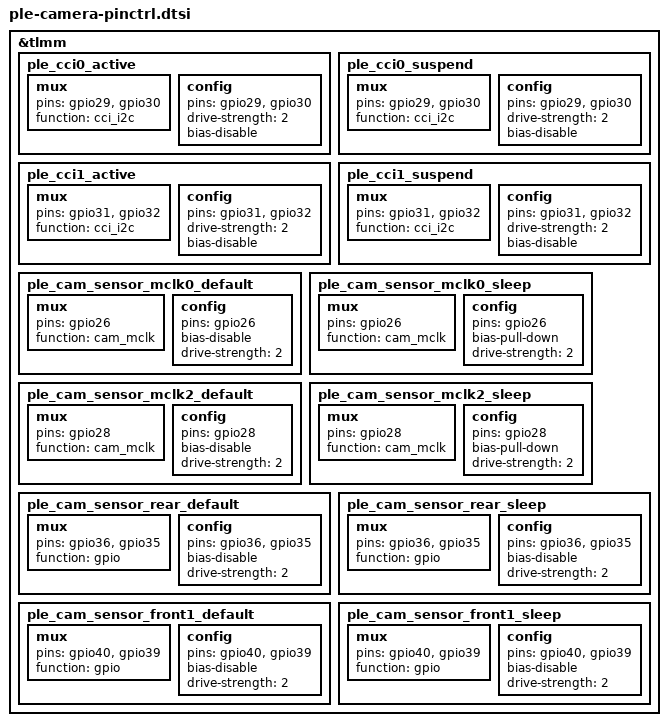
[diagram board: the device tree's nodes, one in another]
// SPDX-License-Identifier: GPL-2.0-only
/* Copyright (c) 2015-2016, The Linux Foundation. All rights reserved.
 * Exact PLE619F pin groups from HMD d548dae4af7fa5a75be88ce2e93f95ad4c867777,
 * msm8937-pinctrl-PLE.dtsi. Local labels avoid generic board assumptions.
 */
&tlmm {
	ple_cci0_active: ple_cci0_active {
				/* cci0 active state */
				mux {
					/* CLK, DATA */
					pins = "gpio29", "gpio30";
					function = "cci_i2c";
				};

				config {
					pins = "gpio29", "gpio30";
					drive-strength = <2>; /* 2 MA */
					bias-disable; /* No PULL */
				};
			};
	ple_cci0_suspend: ple_cci0_suspend {
				/* cci0 suspended state */
				mux {
					/* CLK, DATA */
					pins = "gpio29", "gpio30";
					function = "cci_i2c";
				};

				config {
					pins = "gpio29", "gpio30";
					drive-strength = <2>; /* 2 MA */
					bias-disable; /* No PULL */
				};
			};
	ple_cci1_active: ple_cci1_active {
				/* cci1 active state */
				mux {
					/* CLK, DATA */
					pins = "gpio31", "gpio32";
					function = "cci_i2c";
				};

				config {
					pins = "gpio31", "gpio32";
					drive-strength = <2>; /* 2 MA */
					bias-disable; /* No PULL */
				};
			};
	ple_cci1_suspend: ple_cci1_suspend {
				/* cci1 suspended state */
				mux {
					/* CLK, DATA */
					pins = "gpio31", "gpio32";
					function = "cci_i2c";
				};

				config {
					pins = "gpio31", "gpio32";
					drive-strength = <2>; /* 2 MA */
					bias-disable; /* No PULL */
				};
			};
	ple_cam_sensor_mclk0_default: ple_cam_sensor_mclk0_default {
			/* MCLK0 */
			mux {
				/* CLK, DATA */
				pins = "gpio26";
				function = "cam_mclk";
			};

			config {
				pins = "gpio26";
				bias-disable; /* No PULL */
				drive-strength = <2>; /* 2 MA */
			};
		};
	ple_cam_sensor_mclk0_sleep: ple_cam_sensor_mclk0_sleep {
			/* MCLK0 */
			mux {
				/* CLK, DATA */
				pins = "gpio26";
				function = "cam_mclk";
			};

			config {
				pins = "gpio26";
				bias-pull-down; /* PULL DOWN */
				drive-strength = <2>; /* 2 MA */
			};
		};
	ple_cam_sensor_mclk2_default: ple_cam_sensor_mclk2_default {
			/* MCLK2 */
			mux {
				/* CLK, DATA */
				pins = "gpio28";
				function = "cam_mclk";
			};

			config {
				pins = "gpio28";
				bias-disable; /* No PULL */
				drive-strength = <2>; /* 2 MA */
			};
		};
	ple_cam_sensor_mclk2_sleep: ple_cam_sensor_mclk2_sleep {
			/* MCLK2 */
			mux {
				/* CLK, DATA */
				pins = "gpio28";
				function = "cam_mclk";
			};

			config {
				pins = "gpio28";
				bias-pull-down; /* PULL DOWN */
				drive-strength = <2>; /* 2 MA */
			};
		};
	ple_cam_sensor_rear_default: ple_cam_sensor_rear_default {
			/* RESET, STANDBY */
			mux {
				pins = "gpio36", "gpio35";
				function = "gpio";
			};

			config {
				pins = "gpio36","gpio35";
				bias-disable; /* No PULL */
				drive-strength = <2>; /* 2 MA */
			};
		};
	ple_cam_sensor_rear_sleep: ple_cam_sensor_rear_sleep {
			/* RESET, STANDBY */
			mux {
				pins = "gpio36","gpio35";
				function = "gpio";
			};

			config {
				pins = "gpio36","gpio35";
				bias-disable; /* No PULL */
				drive-strength = <2>; /* 2 MA */
			};
		};
	ple_cam_sensor_front1_default: ple_cam_sensor_front1_default {
			/* RESET, STANDBY */
			mux {
				pins = "gpio40", "gpio39";
				function = "gpio";
			};

			config {
				pins = "gpio40", "gpio39";
				bias-disable; /* No PULL */
				drive-strength = <2>; /* 2 MA */
			};
		};
	ple_cam_sensor_front1_sleep: ple_cam_sensor_front1_sleep {
			/* RESET, STANDBY */
			mux {
				pins = "gpio40", "gpio39";
				function = "gpio";
			};

			config {
				pins = "gpio40", "gpio39";
				bias-disable; /* No PULL */
				drive-strength = <2>; /* 2 MA */
			};
		};
};
